# R7FA6T2BD register map
Vendor: Renesas Electronics Corporation; Series: RA6; File version: 1.40.00
CPU: CM33 r0p4, little endian, MPU, FPU, VTOR, 4 interrupt priority bits, 96 interrupts
Registers are 32-bit, read-write, reset 0x0 unless marked. A register's access mark holds for its fields unless they carry their own. Offsets are from the block's base; [hi:lo] are bit positions.

## PSCU — Peripheral Security Control Unit
Base 0x400E0000
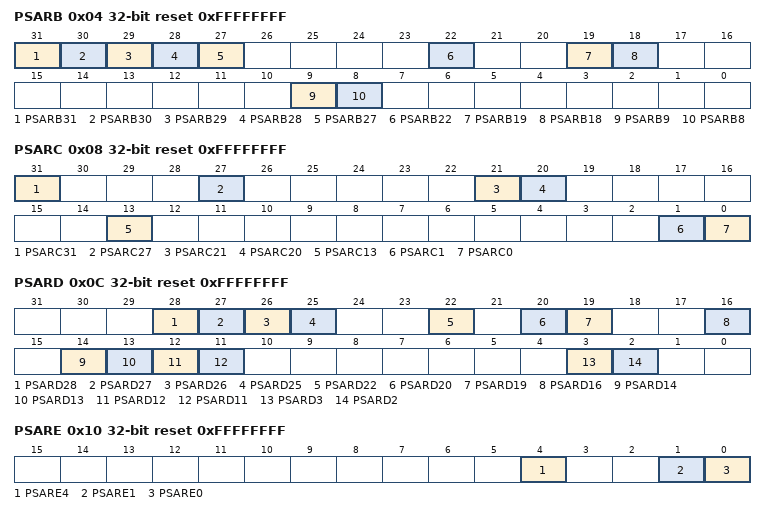
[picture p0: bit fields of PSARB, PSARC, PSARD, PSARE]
0x04 PSARB reset 0xFFFFFFFF — Peripheral Security Attribution Register B
  [all] fields
    0=Secure; 1=Non-secure
  [31] PSARB31 — SCI0 and the MSTPCRB.MSTPB31 bit security attribution
  [30] PSARB30 — SCI1 and the MSTPCRB.MSTPB30 bit security attribution
  [29] PSARB29 — SCI2 and the MSTPCRB.MSTPB29 bit security attribution
  [28] PSARB28 — SCI3 and the MSTPCRB.MSTPB28 bit security attribution
  [27] PSARB27 — SCI4 and the MSTPCRB.MSTPB27 bit security attribution
  [22] PSARB22 — SCI9 and the MSTPCRB.MSTPB22 bit security attribution
  [19] PSARB19 — SPI0 and the MSTPCRB.MSTPB19 bit security attribution
  [18] PSARB18 — SPI1 and the MSTPCRB.MSTPB18 bit security attribution
  [9] PSARB9 — IIC0 and the MSTPCRB.MSTPB9 bit security attribution
  [8] PSARB8 — IIC1 and the MSTPCRB.MSTPB8 bit security attribution
0x08 PSARC reset 0xFFFFFFFF — Peripheral Security Attribution Register C
  [all] fields
    0=Secure; 1=Non-secure
  [31] PSARC31 — SCE5 and the MSTPCRC.MSTPC31 bit security attribution
  [27] PSARC27 — CANFD and the MSTPCRC.MSTPC27 bit security attribution
  [21] PSARC21 — IIRFA and the MSTPCRC.MSTPC21 bit security attribution
  [20] PSARC20 — TFU and the MSTPCRC.MSTPC20 bit security attribution
  [13] PSARC13 — DOC and the MSTPCRC.MSTPC13 bit security attribution
  [1] PSARC1 — CRC and the MSTPCRC.MSTPC1 bit security attribution
  [0] PSARC0 — CAC and the MSTPCRC.MSTPC0 bit security attribution
0x0C PSARD reset 0xFFFFFFFF — Peripheral Security Attribution Register D
  [all] fields
    0=Secure; 1=Non-secure
  [28] PSARD28 — ACMPHS0 and the MSTPCRD.MSTPD28 bit security attribution
  [27] PSARD27 — ACMPHS1 and the MSTPCRD.MSTPD27 bit security attribution
  [26] PSARD26 — ACMPHS2 and the MSTPCRD.MSTPD26 bit security attribution
  [25] PSARD25 — ACMPHS3 and the MSTPCRD.MSTPD25 bit security attribution
  [22] PSARD22 — TSN and the MSTPCRD.MSTPD22 bit security attribution
  [20] PSARD20 — DAC12 unit0 and the MSTPCRD.MSTPD20 bit security attribution
  [19] PSARD19 — DAC12 unit1 and the MSTPCRD.MSTPD19 bit security attribution
  [16] PSARD16 — ADC and the MSTPCRD.MSTPD16 bit security attribution
  [14] PSARD14 — POEG Group A and the MSTPCRD.MSTPD14 bit security attribution
  [13] PSARD13 — POEG Group B and the MSTPCRD.MSTPD13 bit security attribution
  [12] PSARD12 — POEG Group C and the MSTPCRD.MSTPD12 bit security attribution
  [11] PSARD11 — POEG Group D and the MSTPCRD.MSTPD11 bit security attribution
  [3] PSARD3 — AGT0 and the MSTPCRD.MSTPD3 bit security attribution
  [2] PSARD2 — AGT1 and the MSTPCRD.MSTPD2 bit security attribution
0x10 PSARE reset 0xFFFFFFFF — Peripheral Security Attribution Register E
  [all] fields
    0=Secure; 1=Non-secure
  [4] PSARE4 — KINT and the MSTPCRE.MSTPE4 bit security attribution
  [1] PSARE1 — IWDT security attribution
  [0] PSARE0 — WDT security attribution
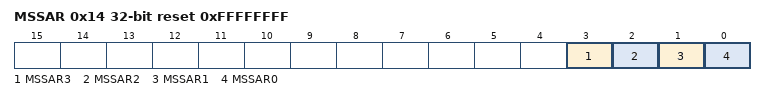
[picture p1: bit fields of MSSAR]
0x14 MSSAR reset 0xFFFFFFFF — Module Stop Security Attribution Register
  [all] fields
    0=Secure; 1=Non-secure
  [3] MSSAR3 — The MSTPCRA.MSTPA0 bit security attribution
  [2] MSSAR2 — The MSTPCRA.MSTPA7 bit security attribution
  [1] MSSAR1 — The MSTPCRA.MSTPA22 bit security attribution
  [0] MSSAR0 — The MSTPCRC.MSTPC14 bit security attribution
0x18 CFSAMONA ro (reset mask 0xFF007FFF) — Code Flash Security Attribution Monitor Register A
  [23:15] CFS2 — Code Flash Secure area 2
0x1C CFSAMONB ro (reset mask 0xFF0003FF) — Code Flash Security Attribution Monitor Register B
  [23:10] CFS1 — Code Flash Secure area 1
0x20 DFSAMON ro (reset mask 0xFFFF03FF) — Data Flash Security Attribution Monitor Register
  [15:10] DFS — Data flash Secure area
0x24 SSAMONA ro (reset mask 0xFFE01FFF) — SRAM Security Attribution Monitor Register A
  [20:13] SS2 — SRAM Secure area 2
0x28 SSAMONB ro (reset mask 0xFFE003FF) — SRAM Security Attribution Monitor Register B
  [20:10] SS1 — SRAM secure area 1
0x2C DLMMON ro (reset mask 0xFFFFFFF0) — Device Lifecycle Management State Monitor Register
  [3:0] DLMMON — Device Lifecycle Management State Monitor
    1=CM; 2=SSD; 3=NSECSD; 4=DPL; 5=LCK_DBG; 6=LCK_BOOT; 7=RMA_REQ; 8=RMA_ACK; other=Others (Reserved)
